# RL6955_IP_SVD register map
Vendor: Realtek
Registers are 32-bit, read-write, reset 0x0 unless marked. A register's access mark holds for its fields unless they carry their own. Offsets are from the block's base; [hi:lo] are bit positions; {n}, {i} and the like mark numbered series; 'fields as' and 'values as' point back to an identical list.

## SPI0_REG
Base 0x41885000
Same registers: SPI1_REG 0x41886000
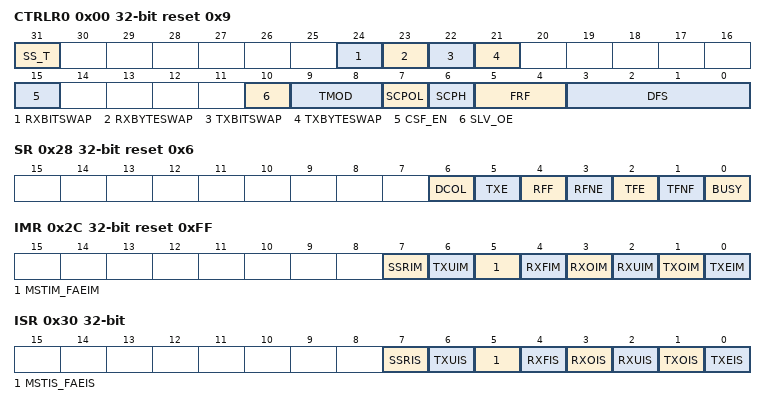
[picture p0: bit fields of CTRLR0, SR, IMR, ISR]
0x00 CTRLR0 reset 0x9 — Control Register 0
  [31] SS_T — When SCPH is 0 (Relevant only when the SPI is configured as a serial-master device) 0: ss_n_out doesn't toggle between successive frames 1: ss_n_out does toggle between successive frames
  [24] RXBITSWAP — 0: Order of receive bit doesn't swap 1: Order of receive bit does swap
  [23] RXBYTESWAP — 0: Order of receive byte doesn't swap 1: Order of receive byte does swap
  [22] TXBITSWAP — 0: Order of transmit bit doesn't swap 1: Order of transmit bit does swap
  [21] TXBYTESWAP — 0: Order of transmit byte doesn't swap 1: Order of transmit byte does swap
  [15] CSF_EN — CS Force Control Enable. Relevant only when the SPI is configured as a serial-master device. This bit field enable SPI to force CS signal keep low until the amount of data bits (DFS * NDF) had been sent/received. SPI master will force the CS signal low even when the TX FIFO is empty during transmission. 0: CS Force Control is disabled. 1: CS Force Control is enabled.
  [10] SLV_OE — Slave Output Enable. Relevant only when the SPI is configured as a serial-slave device. When configured as a serial master, this bit field has no functionality. This bit enables or disables the setting of the ssi_oe_n output from the SPI serial slave. When SLV_OE = 1, the ssi_oe_n output can never be active. When the ssi_oe_n output controls the tri-state buffer on the txd output from the slave, a high impedance state is always present on the slave txd output when SLV_OE = 1. This is useful when the master transmits in broadcast mode (master transmits data to all slave devices). Only one slave may respond with data on the master rxd line. This bit is enabled after reset and must be disabled by software (when broadcast mode is used), if you do not want this device to respond with data. 0: Slave txd is enabled 1: Slave txd is disabled
  [9:8] TMOD — Transfer Mode. Relevant only when the SPI is configured as a serial-master device. Selects the mode of transfer for serial communication. This field does not affect the transfer duplicity. Only indicates whether the receive or transmit data are valid. In transmit-only mode, data received from the external device is not valid and is not stored in the receive FIFO memory; it is overwritten on the next transfer. In receive-only mode, transmitted data are not valid. After the first write to the transmit FIFO, the same word is retransmitted for the duration of the transfer. In transmit-and-receive mode, both transmit and receive data are valid. The transfer continues until the transmit FIFO is empty. Data received from the external device are stored into the receive FIFO memory, where it can be accessed by the host processor. 00: Transmit & Receive 01: Transmit Only 10: Receive Only
  [7] SCPOL — Serial Clock Polarity. Valid when the frame format (FRF) is set to Motorola SPI. Used to select the polarity of the inactive serial clock, which is held inactive when the SPI master is not actively transferring data on the serial bus. 0: Inactive state of serial clock is low 1: Inactive state of serial clock is high
  [6] SCPH — Serial Clock Phase. Valid when the frame format (FRF) is set to Motorola SPI. The serial clock phase selects the relationship of the serial clock with the slave select signal. When SCPH = 0, data are captured on the first edge of the serial clock. When SCPH = 1, the serial clock starts toggling one cycle after the slave select line is activated, and data are captured on the second edge of the serial clock. 0: Serial clock toggles in middle of the first data bit 1: Serial clock toggles at start of the first data bit
  [5:4] FRF — Frame Format. Selects which serial protocol transfers the data. 00: Motorola SPI Other: Reserved
  [3:0] DFS — Data Frame Size. Selects the data frame length. When the data frame size is programmed to be less than 16 bits, the receive data are automatically right-justified by the receive logic, with the upper bits of the receive FIFO zero-padded. You must right-justify transmit data before writing into the transmit FIFO. The transmit logic ignores the upper unused bits when transmitting the data. For the DFS decode, refer to the following description: 0000/0001/0010: Reserved (undefined operation) 0011: 4-bit serial data transfer 0100: 5-bit serial data transfer 0101: 6-bit serial data transfer 0110: 7-bit serial data transfer 0111: 8-bit serial data transfer 1000: 9-bit serial data transfer 1001: 10-bit serial data transfer 1010: 11-bit serial data transfer 1011: 12-bit serial data transfer 1100: 13-bit serial data transfer 1101: 14-bit serial data transfer 1110: 15-bit serial data transfer 1111: 16-bit serial data transfer
0x04 CTRLR1 — Control Register 1
  [15:0] NDF — Number of Data Frames. When TMOD = 10 or TMOD = 11, this register field sets the number of data frames to be continuously received by the SPI. The SPI continues to receive serial data until the number of data frames received is equal to this register value plus 1, which enables you to receive up to 64 KB of data in a continuous transfer. When the SPI is configured as a serial slave, the transfer continues for as long as the slave is selected. Therefore, this register serves no purpose and is not present when the SPI is configured as a serial slave. When CFS_EN is enabled, this bit field will be taken by SPI master to calculate the amount of data bits for all TMOD.
0x08 SSIENR — SSI Enable Register
  [0] SSI_EN — SPI Enable. Enables and disables all SPI operations. When disabled, all serial transfers are halted immediately. Transmit and receive FIFO buffers are cleared when the device is disabled. It is impossible to program some of the SPI control registers when enabled. When disabled, the ssi_sleep output is set (after delay) to inform the system that it is safe to remove the ssi_clk, thus saving power consumption in the system.
0x10 SER — Slave Enable Register
  [0] SER — Slave Select Enable Flag. When this bit is set (1), the corresponding slave select line from the master is activated when a serial transfer begins. It should be noted that setting or clearing bits in this register have no effect on the corresponding slave select outputs until a transfer is started. Before beginning a transfer, you should enable the bit in this register that corresponds to the slave device with which the master wants to communicate. 1: Selected 0: Not selected
0x14 BAUDR — Baud Rate Select
  [15:0] SCKDV — SPI Clock Divider. The LSB for this field is always set to 0 and is unaffected by a write operation, which ensures an even value is held in this register. If the value is 0, the serial output clock (sclk_out) is disabled. The frequency of the sclk_out is derived from the equation: Fsclk_out =Fssi_clk/SCKDV, where SCKDV is any even value between 2 and 65534.
0x18 TXFTLR — Transmit FIFO Threshold Level
  [5:0] TFT — Transmit FIFO Threshold. Controls the level of entries (or below) at which the transmit FIFO controller triggers an interrupt. The FIFO depth is 64; this register is sized to the number of address bits needed to access the FIFO. If you attempt to set this value greater than or equal to the depth of the FIFO, this field is not written and retains its current value. When the number of transmit FIFO entries is less than or equal to this value, the transmit FIFO empty interrupt is triggered. For TFT decode, refer to the following description: 000000: ssi_txe_intr is asserted when 0 data entry is present in transmit FIFO. 000001: ssi_txe_intr is asserted when 1 data entry is present in transmit FIFO. 000010: ssi_txe_intr is asserted when 2 data entries are present in transmit FIFO. 000011: ssi_txe_intr is asserted when 3 data entries are present in transmit FIFO. ... 111100: ssi_txe_intr is asserted when 60 data entries are present in transmit FIFO. 111101: ssi_txe_intr is asserted when 61 data entries are present in transmit FIFO. 111110: ssi_txe_intr is asserted when 62 data entries are present in transmit FIFO. 111111: ssi_txe_intr is asserted when 63 data entries are present in transmit FIFO.
0x1C RXFTLR — Receive FIFO Threshold Level
  [5:0] RFT — Receive FIFO Threshold. Controls the level of entries (or above) at which the receive FIFO controller triggers an interrupt. The FIFO depth is configurable in the range 2~64. This register is sized to the number of address bits needed to access the FIFO. If you attempt to set this value greater than the depth of the FIFO, this field is not written and retains its current value. When the number of receive FIFO entries is greater than or equal to this value + 1, the receive FIFO full interrupt is triggered. For RFT decode, refer to the following description: 000000: ssi_rxf_intr is asserted when 1 or more data entries are present in receive FIFO. 000001: ssi_rxf_intr is asserted when 2 or more data entries are present in receive FIFO. 000010: ssi_rxf_intr is asserted when 3 or more data entries are present in receive FIFO. 000011: ssi_rxf_intr is asserted when 4 or more data entries are present in receive FIFO. ... 111110: ssi_rxf_intr is asserted when 61 or more data entries are present in receive FIFO. 111101: ssi_rxf_intr is asserted when 62 or more data entries are present in receive FIFO. 111110: ssi_rxf_intr is asserted when 63 or more data entries are present in receive FIFO. 111111: ssi_rxf_intr is asserted when 64 or more data entries are present in receive FIFO.
0x20 TXFLR ro — Transmit FIFO Level Register
  [6:0] TXTFL — Transmit FIFO Level. Contains the number of valid data entries in the transmit FIFO.
0x24 RXFLR ro — Receive FIFO Level Register
  [6:0] RXTFL — Receive FIFO Level. Contains the number of valid data entries in the receive FIFO.
0x28 SR ro reset 0x6 — Status Register
  [6] DCOL — Data Collision Error. Relevant only when the SPI is configured as a master device. This bit is set if the SPI master is actively transmitting when another master selects this device as a slave. This informs the processor that the last data transfer was halted before completion. This bit is cleared when read. 0: No error 1: Transmit data collision error
  [5] TXE — Transmission Error. Set if the transmit FIFO is empty when a transfer is started. This bit can be set only when the SPI is configured as a slave device. Data from the previous transmission is resent on the txd line. This bit is cleared when read. 0: No error 1: Transmission error
  [4] RFF — Receive FIFO Full. When the receive FIFO is completely full, this bit is set. When the receive FIFO contains one or more empty location, this bit is cleared. 0: Receive FIFO is not full 1: Receive FIFO is full
  [3] RFNE — Receive FIFO Not Empty. Set when the receive FIFO contains one or more entries and is cleared when the receive FIFO is empty. This bit can be polled by software to completely empty the receive FIFO. 0: Receive FIFO is empty 1: Receive FIFO is not empty
  [2] TFE — Transmit FIFO Empty. When the transmit FIFO is completely empty, this bit is set. When the transmit FIFO contains one or more valid entries, this bit is cleared. This bit field does not request an interrupt. 0: Transmit FIFO is not empty 1: Transmit FIFO is empty
  [1] TFNF — Transmit FIFO Not Full. Set when the transmit FIFO contains one or more empty locations, and is cleared when the FIFO is full. 0: Transmit FIFO is full 1: Transmit FIFO is not full
  [0] BUSY — SSI Busy Flag. When set, indicates that a serial transfer is in progress; when cleared indicates that the SPI is idle or disabled. 0: SPI is idle or disabled 1: SPI is actively transferring data
0x2C IMR reset 0xFF — Interrupt Mask Register
  [7] SSRIM — SS_N Rising Edge Detect Interrupt Mask. This bit field is present only if the SPI is configured as a serial-slave device. 0: ssi_ssr_intr is masked 1: ssi_ssr_intr is not masked
  [6] TXUIM — Transmit FIFO Underflow Interrupt Mask. This bit field is present only if the SPI is configured as a serial-slave device. 0: ssi_txu_intr is masked 1: ssi_txu_intr is not masked
  [5] MSTIM_FAEIM — When SPI is configured as serial-master, this bit field is present as Multi-Master Contention Interrupt Mask. 0: ssi_mst_intr interrupt is masked 1: ssi_mst_intr interrupt is not masked When SPI is configured as serial-slave, this bit field is present as Frame Alignment Interrupt Mask. 0: ssi_fae_intr interrupt is masked 1: ssi_fae_intr interrupt is not masked
  [4] RXFIM — Receive FIFO Full Interrupt Mask. 0: ssi_rxf_intr interrupt is masked 1: ssi_rxf_intr interrupt is not masked
  [3] RXOIM — Receive FIFO Overflow Interrupt Mask. 0: ssi_rxo_intr interrupt is masked 1: ssi_rxo_intr interrupt is not masked
  [2] RXUIM — Receive FIFO Underflow Interrupt Mask. 0: ssi_rxu_intr interrupt is masked 1: ssi_rxu_intr interrupt is not masked
  [1] TXOIM — Transmit FIFO Overflow Interrupt Mask. 0: ssi_txo_intr interrupt is masked 1: ssi_txo_intr interrupt is not masked
  [0] TXEIM — Transmit FIFO Empty Interrupt Mask. 0: ssi_txe_intr interrupt is masked 1: ssi_txe_intr interrupt is not masked
0x30 ISR ro — Interrupt Status Register
  [7] SSRIS — SS_N Rising Edge Detect Interrupt Status. This bit field is present only if the SPI is configured as a serial-slave device. 0: ssi_ssr_intr interrupt is not active after masking 1: ssi_ssr_intr interrupt is active after masking
  [6] TXUIS — Transmit FIFO Under Flow Interrupt Status. This bit field is present only if the SPI is configured as a serial-slave device. 0: ssi_txu_intr interrupt is not active after masking 1: ssi_txu_intr interrupt is active after masking
  [5] MSTIS_FAEIS — When SPI is configured as serial-master, this bit field is present as Multi-Master Contention Interrupt Status. 0: ssi_mst_intr interrupt is not active after masking 1: ssi_mst_intr interrupt is active after masking When SPI is configured as serial-slave, this bit field is present as Frame Alignment Interrupt Status. 0: ssi_fae_intr interrupt not active after masking 1: ssi_fae_intr interrupt is active after masking
  [4] RXFIS — Receive FIFO Full Interrupt Status. 0: ssi_rxf_intr interrupt is not active after masking 1: ssi_rxf_intr interrupt is full after masking
  [3] RXOIS — Receive FIFO Overflow Interrupt Status. 0: ssi_rxo_intr interrupt is not active after masking 1: ssi_rxo_intr interrupt is active after masking
  [2] RXUIS — Receive FIFO Underflow Interrupt Status. 0: ssi_rxu_intr interrupt is not active after masking 1: ssi_rxu_intr interrupt is active after masking
  [1] TXOIS — Transmit FIFO Overflow Interrupt Status. 0: ssi_txo_intr interrupt is not active after masking 1: ssi_txo_intr interrupt is active after masking
  [0] TXEIS — Transmit FIFO Empty Interrupt Status. 0: ssi_txe_intr interrupt is not active after masking 1: ssi_txe_intr interrupt is active after masking
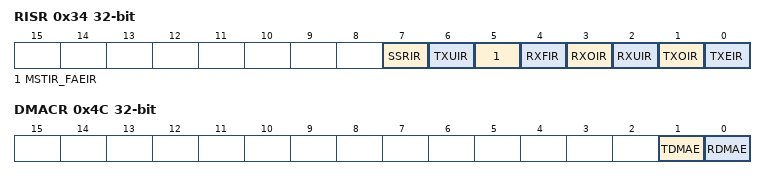
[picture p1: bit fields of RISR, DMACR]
0x34 RISR ro — Raw Interrupt Status Register
  [7] SSRIR — SS_N Rising Edge Detect Raw Interrupt Status. This bit field is present only if the SPI is configured as a serial-slave device. 0: ssi_ssr_intr interrupt is not active prior to masking 1: ssi_ssr_intr interrupt is active prior to masking
  [6] TXUIR — Transmit FIFO Under Flow Raw Interrupt Status. This bit field is present only if the SPI is configured as a serial-slave device. 0: ssi_txu_intr interrupt is not active prior to masking 1: ssi_txu_intr interrupt is active prior to masking
  [5] MSTIR_FAEIR — When SPI is configured as serial-master, this bit field is present as Multi-Master Contention Raw Interrupt Status. 0: ssi_mst_intr interrupt is not active prior to masking 1: ssi_mst_intr interrupt is active prior to masking When SPI is configured as serial-slave, this bit field is present as Frame Alignment Error Raw Interrupt Status. 0: ssi_fae_intr interrupt not active prior to masking 1: ssi_fae_intr interrupt is active prior to masking
  [4] RXFIR — Receive FIFO Full Raw Interrupt Status. 0: ssi_rxf_intr interrupt is not active prior to masking 1: ssi_rxf_intr interrupt is active prior to masking
  [3] RXOIR — Receive FIFO Overflow Raw Interrupt Status. 0: ssi_rxo_intr interrupt is not active prior to masking 1: ssi_rxo_intr interrupt is active prior to masking
  [2] RXUIR — Receive FIFO Underflow Raw Interrupt Status. 0: ssi_rxu_intr interrupt is not active prior to masking 1: ssi_rxu_intr interrupt is active prior to masking
  [1] TXOIR — Transmit FIFO Overflow Raw Interrupt Status. 0: ssi_txo_intr interrupt is not active prior to masking 1: ssi_txo_intr interrupt is active prior to masking
  [0] TXEIR — Transmit FIFO Empty Raw Interrupt Status. 0: ssi_txe_intr interrupt is not active prior to masking 1: ssi_txe_intr interrupt is active prior to masking
0x38 TXOICR ro — Transmit FIFO Overflow Interrupt Clear Register
  [0] TXOICR — Clear Transmit FIFO Overflow Interrupt. This register reflects the status of the interrupt. A read from this register clears the ssi_txo_intr interrupt; writing has no effect.
0x3C RXOICR ro — Receive FIFO Overflow Interrupt Clear Register
  [0] RXOICR — Clear Receive FIFO Overflow Interrupt. This register reflects the status of the interrupt. A read from this register clears the ssi_rxo_intr interrupt; writing has no effect.
0x40 RXUICR ro — Receive FIFO Underflow Interrupt Clear Register
  [0] RXUICR — Clear Receive FIFO Underflow Interrupt. This register reflects the status of the interrupt. A read from this register clears the ssi_rxu_intr interrupt; writing has no effect.
0x44 MSTICR_FAEICR ro — Multi-Master & Frame Alignment Error Interrupt Clear Register
  [0] MSTICR_FAEICR — Multi-Master Interrupt Clear Register/Frame Alignment Error Interrupt Clear Register. When SPI is configured as serial-master, this bit field is used to Clear Multi-Master Contention Interrupt. A read from this register clears the ssi_mst_intr interrupt; writing has no effect. When SPI is configured as serial-slave, this bit field is used to Clear Frame Alignment Interrupt. A read from this register clears the ssi_fae_intr interrupt; writing has no effect.
0x48 ICR ro — Interrupt Clear Register
  [0] ICR — Clear Interrupt. This register is set if any of the interrupts below are active. A read clears the ssi_txo_intr, ssi_rxu_intr, ssi_rxo_intr, and the ssi_mst_intr/ssi_fae_intr interrupts. Writing to this register has no effect.
0x4C DMACR — DMA Control Register
  [1] TDMAE — Transmit DMA Enable. This bit enables/disables the transmit FIFO DMA channel. 0: Transmit DMA disabled 1: Transmit DMA enabled
  [0] RDMAE — Receive DMA Enable. This bit enables/disables the receive FIFO DMA channel 0: Receive DMA disabled 1: Receive DMA enabled
0x50 DMATDLR — DMA Transmit Data Level
  [5:0] DMATDL — Transmit Data Level. This bit field controls the level at which a DMA request is made by the transmit logic. It is equal to the watermark level; that is, the dma_tx_req signal is generated when the number of valid data entries in the transmit FIFO is equal to or below this field value, and TDMAE = 1. For DMATDL decode, refer to the following description: 000000: dma_tx_req is asserted when 0 data entry is present in transmit FIFO. 000001: dma_tx_req is asserted when 1 data entry is present in transmit FIFO. 000010: dma_tx_req is asserted when 2 data entries are present in transmit FIFO. 000011: dma_tx_req is asserted when 3 data entries are present in transmit FIFO. ... 111100: dma_tx_req is asserted when 60 data entries are present in transmit FIFO. 111101: dma_tx_req is asserted when 61 data entries are present in transmit FIFO. 111110: dma_tx_req is asserted when 62 data entries are present in transmit FIFO. 111111: dma_tx_req is asserted when 63 data entries are present in transmit FIFO.
0x54 DMARDLR — DMA Receive Data Level
  [5:0] DMARDL — Receive Data Level. This bit field controls the level at which a DMA request is made by the receive logic. The watermark level = DMARDL+1; that is, dma_rx_req is generated when the number of valid data entries in the receive FIFO is equal to or above this field value + 1, and RDMAE=1. For DMARDL decode, refer to the following description: 000000: dma_rx_req is asserted when 1 or more data entries are present in transmit FIFO. 000001: dma_rx_req is asserted when 2 or more data entries are present in transmit FIFO. 000010: dma_rx_req is asserted when 3 or more data entries are present in transmit FIFO. 000011: dma_rx_req is asserted when 4 or more data entries are present in transmit FIFO. ... 111100: dma_rx_req is asserted when 61 or more data entries are present in transmit FIFO. 111101: dma_rx_req is asserted when 62 or more data entries are present in transmit FIFO. 111110: dma_rx_req is asserted when 63 or more data entries are present in transmit FIFO. 111111: dma_rx_req is asserted when 64 data entries are present in transmit FIFO.
0x58 TXUICR ro — Transmit FIFO Underflow Interrupt Clear Register
  [0] TXUICR — When SPI is configured as serial-slave, this register is used to Clear Transmit FIFO Underflow Interrupt. This register reflects the status of the interrupt. A read from this register clears the ssi_txu_intr interrupt; writing has no effect.
0x5C SSRICR ro — SS_N Rising Edge Detect Interrupt Clear Register
  [0] SSRICR — When SPI is configured as serial-slave, this register is used to Clear SS_N Rinsing Edge Detect Interrupt. This register reflects the status of the interrupt. A read from this register clears the ssi_ssr_intr interrupt; writing has no effect.
{0x60+4i} DR{i} (i=0..21) — Data Register {i}
  [15:0] DR{i} — Data Register. When writing to this register, you must right-justify the data. Read data are automatically right-justified. Read: Receive FIFO buffer Write: Transmit FIFO buffer
{0x60+4i} DR{i} (i=23..35) — Data Register {i}
  fields as DR0
0xF0 RX_SAMPLE_DLY — rxd Sample Delay Register
  [7:0] RSD — Receive Data (rxd) Sample Delay. This register is used to delay the sample of the rxd input signal. Each value represents a single ssi_clk delay on the sample of the rxd signal.
0x100 SPI_DUMMY ro
  [15:0] dummy — rsvd for hw
